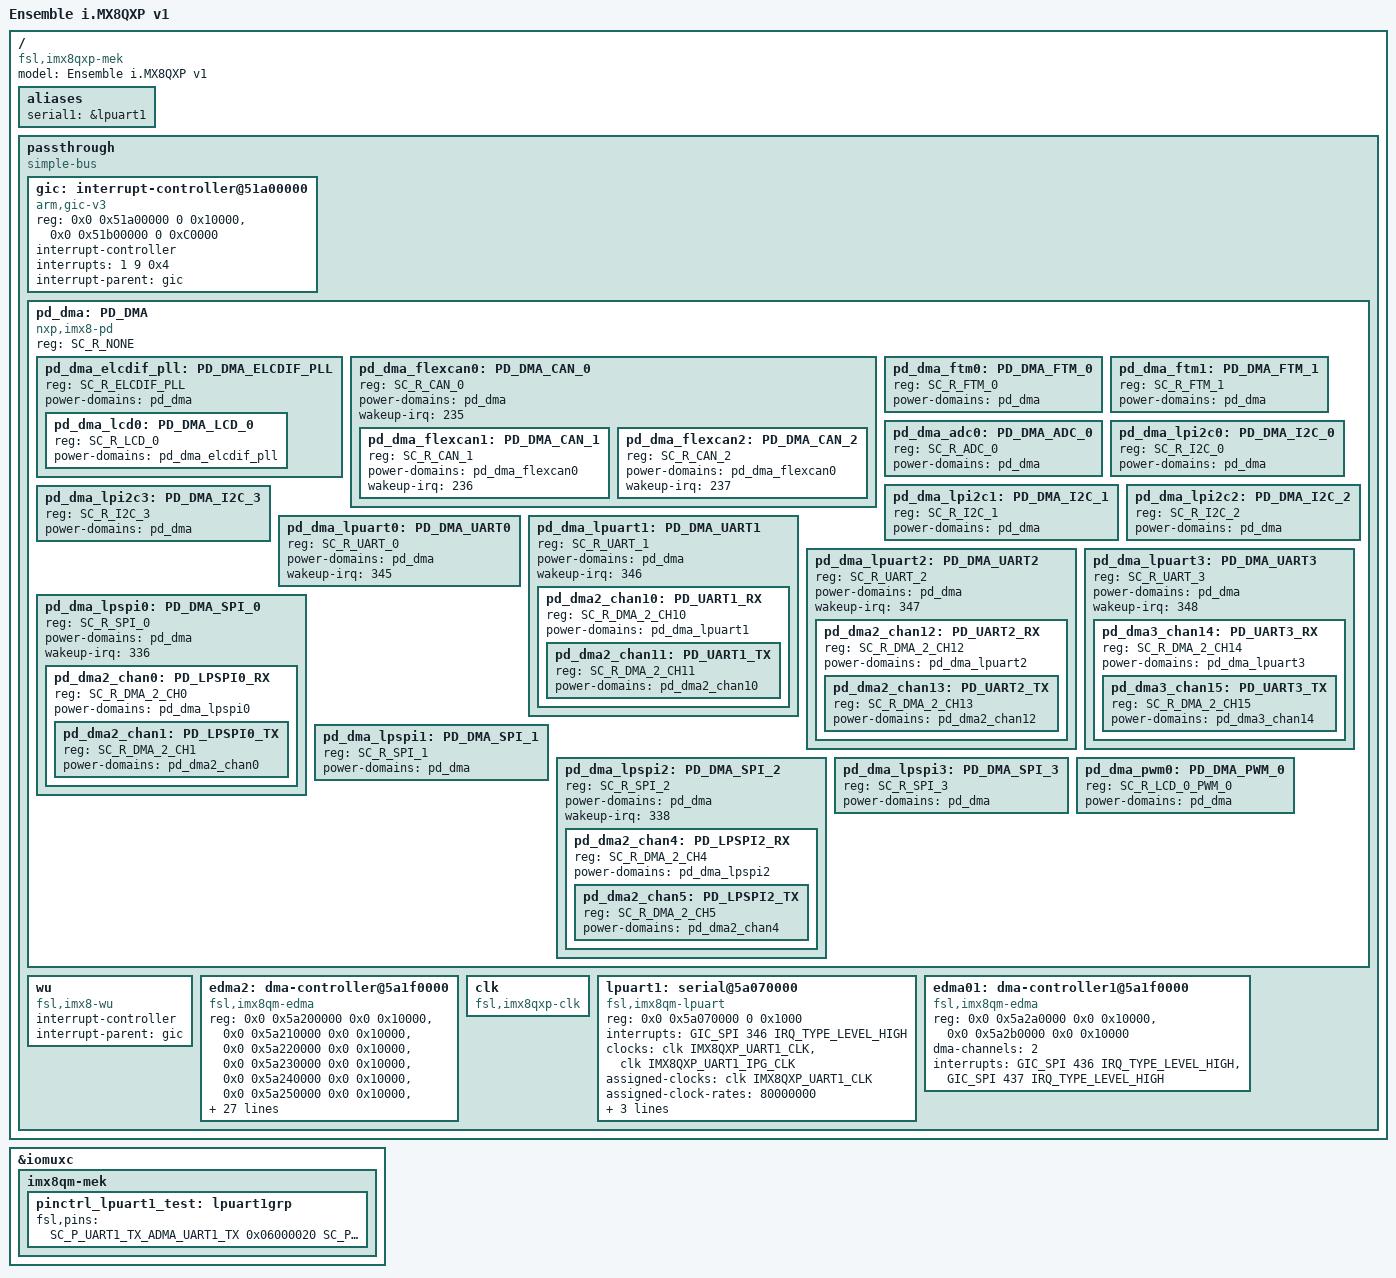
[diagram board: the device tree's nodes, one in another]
/*
 * Copyright 2017-2018 NXP
 *
 * This program is free software; you can redistribute it and/or
 * modify it under the terms of the GNU General Public License
 * as published by the Free Software Foundation; either version 2
 * of the License, or (at your option) any later version.
 *
 * This program is distributed in the hope that it will be useful,
 * but WITHOUT ANY WARRANTY; without even the implied warranty of
 * MERCHANTABILITY or FITNESS FOR A PARTICULAR PURPOSE.  See the
 * GNU General Public License for more details.
 */

/dts-v1/;

#include <dt-bindings/soc/imx_rsrc.h>


/ {
   model = "Ensemble i.MX8QXP v1";	compatible = "fsl,imx8qxp-mek", "fsl,imx8qxp";
    aliases {
    	serial1 = &lpuart1;
	};

    passthrough {
        compatible = "simple-bus";
        ranges;
        #address-cells = <0x2>;
        #size-cells = <0x2>;

        gic: interrupt-controller@51a00000 {
            compatible = "arm,gic-v3";
            reg = <0x0 0x51a00000 0 0x10000>, /* GIC Dist */
                <0x0 0x51b00000 0 0xC0000>; /* GICR (RD_base + SGI_base) */
            #interrupt-cells = <3>;
            interrupt-controller;
            interrupts = <1 9 0x4>;
            interrupt-parent = <&gic>;
        };

		pd_dma: PD_DMA {
			compatible = "nxp,imx8-pd";
			reg = <SC_R_NONE>;
			#power-domain-cells = <0>;
			#address-cells = <1>;
			#size-cells = <0>;

			pd_dma_elcdif_pll: PD_DMA_ELCDIF_PLL {
				reg = <SC_R_ELCDIF_PLL>;
				#power-domain-cells = <0>;
				power-domains = <&pd_dma>;
				#address-cells = <1>;
				#size-cells = <0>;

				pd_dma_lcd0: PD_DMA_LCD_0 {
					reg = <SC_R_LCD_0>;
					#power-domain-cells = <0>;
					power-domains = <&pd_dma_elcdif_pll>;
				};
			};
			pd_dma_flexcan0: PD_DMA_CAN_0 {
				reg = <SC_R_CAN_0>;
				#power-domain-cells = <0>;
				power-domains = <&pd_dma>;
				wakeup-irq = <235>;
				#address-cells = <1>;
				#size-cells = <0>;

				pd_dma_flexcan1: PD_DMA_CAN_1 {
					reg = <SC_R_CAN_1>;
					#power-domain-cells = <0>;
					power-domains = <&pd_dma_flexcan0>;
					wakeup-irq = <236>;
				};

				pd_dma_flexcan2: PD_DMA_CAN_2 {
					reg = <SC_R_CAN_2>;
					#power-domain-cells = <0>;
					power-domains = <&pd_dma_flexcan0>;
					wakeup-irq = <237>;
				};
			};

			pd_dma_ftm0: PD_DMA_FTM_0 {
				reg = <SC_R_FTM_0>;
				#power-domain-cells = <0>;
				power-domains = <&pd_dma>;
			};
			pd_dma_ftm1: PD_DMA_FTM_1 {
				reg = <SC_R_FTM_1>;
				#power-domain-cells = <0>;
				power-domains = <&pd_dma>;
			};
			pd_dma_adc0: PD_DMA_ADC_0 {
				reg = <SC_R_ADC_0>;
				#power-domain-cells = <0>;
				power-domains = <&pd_dma>;
			};
			pd_dma_lpi2c0: PD_DMA_I2C_0 {
				reg = <SC_R_I2C_0>;
				#power-domain-cells = <0>;
				power-domains = <&pd_dma>;
			};
			pd_dma_lpi2c1: PD_DMA_I2C_1 {
				reg = <SC_R_I2C_1>;
				#power-domain-cells = <0>;
				power-domains = <&pd_dma>;
			};
			pd_dma_lpi2c2:PD_DMA_I2C_2 {
				reg = <SC_R_I2C_2>;
				#power-domain-cells = <0>;
				power-domains = <&pd_dma>;
			};
			pd_dma_lpi2c3: PD_DMA_I2C_3 {
				reg = <SC_R_I2C_3>;
				#power-domain-cells = <0>;
				power-domains = <&pd_dma>;
			};
			pd_dma_lpuart0: PD_DMA_UART0 {
				reg = <SC_R_UART_0>;
				#power-domain-cells = <0>;
				power-domains = <&pd_dma>;
				wakeup-irq = <345>;
			};
			pd_dma_lpuart1: PD_DMA_UART1 {
				reg = <SC_R_UART_1>;
				#power-domain-cells = <0>;
				power-domains = <&pd_dma>;
				#address-cells = <1>;
				#size-cells = <0>;
				wakeup-irq = <346>;

				pd_dma2_chan10: PD_UART1_RX {
					reg = <SC_R_DMA_2_CH10>;
					power-domains =<&pd_dma_lpuart1>;
					#power-domain-cells = <0>;
					#address-cells = <1>;
					#size-cells = <0>;

					pd_dma2_chan11: PD_UART1_TX {
						reg = <SC_R_DMA_2_CH11>;
						power-domains =<&pd_dma2_chan10>;
						#power-domain-cells = <0>;
						#address-cells = <1>;
						#size-cells = <0>;
					};
				};
			};
			pd_dma_lpuart2: PD_DMA_UART2 {
				reg = <SC_R_UART_2>;
				#power-domain-cells = <0>;
				power-domains = <&pd_dma>;
				#address-cells = <1>;
				#size-cells = <0>;
				wakeup-irq = <347>;

				pd_dma2_chan12: PD_UART2_RX {
					reg = <SC_R_DMA_2_CH12>;
					power-domains =<&pd_dma_lpuart2>;
					#power-domain-cells = <0>;
					#address-cells = <1>;
					#size-cells = <0>;

					pd_dma2_chan13: PD_UART2_TX {
						reg = <SC_R_DMA_2_CH13>;
						power-domains =<&pd_dma2_chan12>;
						#power-domain-cells = <0>;
						#address-cells = <1>;
						#size-cells = <0>;
					};
				};
			};
			pd_dma_lpuart3: PD_DMA_UART3 {
				reg = <SC_R_UART_3>;
				#power-domain-cells = <0>;
				power-domains = <&pd_dma>;
				#address-cells = <1>;
				#size-cells = <0>;
				wakeup-irq = <348>;

				pd_dma3_chan14: PD_UART3_RX {
					reg = <SC_R_DMA_2_CH14>;
					power-domains =<&pd_dma_lpuart3>;
					#power-domain-cells = <0>;
					#address-cells = <1>;
					#size-cells = <0>;

					pd_dma3_chan15: PD_UART3_TX {
						reg = <SC_R_DMA_2_CH15>;
						power-domains =<&pd_dma3_chan14>;
						#power-domain-cells = <0>;
						#address-cells = <1>;
						#size-cells = <0>;
					};
				};
			};
			pd_dma_lpspi0: PD_DMA_SPI_0 {
				reg = <SC_R_SPI_0>;
				#power-domain-cells = <0>;
				power-domains = <&pd_dma>;
				#address-cells = <1>;
				#size-cells = <0>;
				wakeup-irq = <336>;

				pd_dma2_chan0: PD_LPSPI0_RX {
					reg = <SC_R_DMA_2_CH0>;
					power-domains =<&pd_dma_lpspi0>;
					#power-domain-cells = <0>;
					#address-cells = <1>;
					#size-cells = <0>;

					pd_dma2_chan1: PD_LPSPI0_TX {
						reg = <SC_R_DMA_2_CH1>;
						power-domains =<&pd_dma2_chan0>;
						#power-domain-cells = <0>;
						#address-cells = <1>;
						#size-cells = <0>;
					};
				};
			};
			pd_dma_lpspi1: PD_DMA_SPI_1 {
				reg = <SC_R_SPI_1>;
				#power-domain-cells = <0>;
				power-domains = <&pd_dma>;
			};
			pd_dma_lpspi2: PD_DMA_SPI_2 {
				reg = <SC_R_SPI_2>;
				#power-domain-cells = <0>;
				power-domains = <&pd_dma>;
				#address-cells = <1>;
				#size-cells = <0>;
				wakeup-irq = <338>;

				pd_dma2_chan4: PD_LPSPI2_RX {
					reg = <SC_R_DMA_2_CH4>;
					power-domains =<&pd_dma_lpspi2>;
					#power-domain-cells = <0>;
					#address-cells = <1>;
					#size-cells = <0>;

					pd_dma2_chan5: PD_LPSPI2_TX {
						reg = <SC_R_DMA_2_CH5>;
						power-domains =<&pd_dma2_chan4>;
						#power-domain-cells = <0>;
						#address-cells = <1>;
						#size-cells = <0>;
					};
				};
			};
			pd_dma_lpspi3: PD_DMA_SPI_3 {
				reg = <SC_R_SPI_3>;
				#power-domain-cells = <0>;
				power-domains = <&pd_dma>;
			};
			pd_dma_pwm0: PD_DMA_PWM_0 {
				reg = <SC_R_LCD_0_PWM_0>;
				#power-domain-cells = <0>;
				power-domains = <&pd_dma>;
			};
		};

        wu: wu {
            compatible = "fsl,imx8-wu";
            interrupt-controller;
            #interrupt-cells = <3>;
            interrupt-parent = <&gic>;
        };

        edma2: dma-controller@5a1f0000 {
            compatible = "fsl,imx8qm-edma";
            reg = <0x0 0x5a200000 0x0 0x10000>, /* channel0 LPSPI0 rx */
                <0x0 0x5a210000 0x0 0x10000>, /* channel1 LPSPI0 tx */
                <0x0 0x5a220000 0x0 0x10000>, /* channel2 LPSPI1 rx */
                <0x0 0x5a230000 0x0 0x10000>, /* channel3 LPSPI1 tx */
                <0x0 0x5a240000 0x0 0x10000>, /* channel4 LPSPI2 rx */
                <0x0 0x5a250000 0x0 0x10000>, /* channel5 LPSPI2 tx */
                <0x0 0x5a260000 0x0 0x10000>, /* channel6 LPSPI3 rx */
                <0x0 0x5a270000 0x0 0x10000>, /* channel7 LPSPI3 tx */
                <0x0 0x5a280000 0x0 0x10000>, /* channel8 UART0 rx */
                <0x0 0x5a290000 0x0 0x10000>, /* channel9 UART0 tx */
                <0x0 0x5a2a0000 0x0 0x10000>, /* channel10 UART1 rx */
                <0x0 0x5a2b0000 0x0 0x10000>, /* channel11 UART1 tx */
                <0x0 0x5a2c0000 0x0 0x10000>, /* channel12 UART2 rx */
                <0x0 0x5a2d0000 0x0 0x10000>, /* channel13 UART2 tx */
                <0x0 0x5a2e0000 0x0 0x10000>, /* channel14 UART3 rx */
                <0x0 0x5a2f0000 0x0 0x10000>; /* channel15 UART3 tx */
            #dma-cells = <3>;
            dma-channels = <16>;
            interrupts = <GIC_SPI 416 IRQ_TYPE_LEVEL_HIGH>,
                    <GIC_SPI 417 IRQ_TYPE_LEVEL_HIGH>,
                    <GIC_SPI 418 IRQ_TYPE_LEVEL_HIGH>,
                    <GIC_SPI 419 IRQ_TYPE_LEVEL_HIGH>,
                    <GIC_SPI 420 IRQ_TYPE_LEVEL_HIGH>,
                    <GIC_SPI 421 IRQ_TYPE_LEVEL_HIGH>,
                    <GIC_SPI 422 IRQ_TYPE_LEVEL_HIGH>,
                    <GIC_SPI 423 IRQ_TYPE_LEVEL_HIGH>,
                    <GIC_SPI 434 IRQ_TYPE_LEVEL_HIGH>,
                    <GIC_SPI 435 IRQ_TYPE_LEVEL_HIGH>,
                    <GIC_SPI 436 IRQ_TYPE_LEVEL_HIGH>,
                    <GIC_SPI 437 IRQ_TYPE_LEVEL_HIGH>,
                    <GIC_SPI 438 IRQ_TYPE_LEVEL_HIGH>,
                    <GIC_SPI 439 IRQ_TYPE_LEVEL_HIGH>,
                    <GIC_SPI 440 IRQ_TYPE_LEVEL_HIGH>,
                    <GIC_SPI 441 IRQ_TYPE_LEVEL_HIGH>;
            interrupt-names = "edma2-chan0-rx", "edma2-chan1-tx",
                    "edma2-chan2-rx", "edma2-chan3-tx",
                    "edma2-chan4-rx", "edma2-chan5-tx",
                    "edma2-chan6-rx", "edma2-chan7-tx",
                    "edma2-chan8-rx", "edma2-chan9-tx",
                    "edma2-chan10-rx", "edma2-chan11-tx",
                    "edma2-chan12-rx", "edma2-chan13-tx",
                    "edma2-chan14-rx", "edma2-chan15-tx";
            status = "okay";
        };        

        clk: clk {
            compatible = "fsl,imx8qxp-clk";
            #clock-cells = <1>;
        };

        lpuart1: serial@5a070000 {
            compatible = "fsl,imx8qm-lpuart";
            reg = <0x0 0x5a070000 0x0 0x1000>;
            interrupts = <GIC_SPI 346 IRQ_TYPE_LEVEL_HIGH>;
            interrupt-parent = <&wu>;
            clocks = <&clk IMX8QXP_UART1_CLK>,
                <&clk IMX8QXP_UART1_IPG_CLK>;
            clock-names = "per", "ipg";
            assigned-clocks = <&clk IMX8QXP_UART1_CLK>;
            assigned-clock-rates = <80000000>;
            power-domains = <&pd_dma2_chan11>;
            dma-names = "tx","rx";
            dmas = <&edma2 11 0 0>,
                <&edma2 10 0 1>;
            status = "okay";
        };

        edma01: dma-controller1@5a1f0000 {
			compatible = "fsl,imx8qm-edma";
			reg = <0x0 0x5a2a0000 0x0 0x10000>, /* channel10 UART1 rx */
		          <0x0 0x5a2b0000 0x0 0x10000>; /* channel11 UART1 tx */
			#dma-cells = <3>;
			dma-channels = <2>;
			interrupts = <GIC_SPI 436 IRQ_TYPE_LEVEL_HIGH>,
				     <GIC_SPI 437 IRQ_TYPE_LEVEL_HIGH>;
			interrupt-names = "edma0-chan10-rx", "edma0-chan11-tx";
			status = "okay";
		};
    };
};

&lpuart1 {
	/delete-property/ interrupt-parent;
	reg = <0x0 0x5a070000 0 0x1000>;
	dmas = <&edma01 15 0 0>, <&edma01 14 0 1>;
	pinctrl-names = "default";
	pinctrl-0 = <&pinctrl_lpuart1_test>;
	status = "okay";
};

&iomuxc {
	imx8qm-mek {
        pinctrl_lpuart1_test: lpuart1grp {
			fsl,pins = <
				SC_P_UART1_TX_ADMA_UART1_TX		0x06000020
				SC_P_UART1_RX_ADMA_UART1_RX		0x06000020
				SC_P_UART1_RTS_B_ADMA_UART1_RTS_B	0x06000020
				SC_P_UART1_CTS_B_ADMA_UART1_CTS_B	0x06000020
			>;
		};
    };
};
